# AM335x register map
Vendor: Texas Instruments; Series: Sitara AM335x; File version: 1.1
CPU: Cortex-A8 r0p0, little endian
Registers are 32-bit, read-write, reset 0x0 unless marked. A register's access mark holds for its fields unless they carry their own. Offsets are from the block's base; [hi:lo] are bit positions; 'fields as' and 'values as' point back to an identical list.

## EMIF0 — External Memory Interface 4D (EMIF) - DDR Controller
Base 0x4C000000
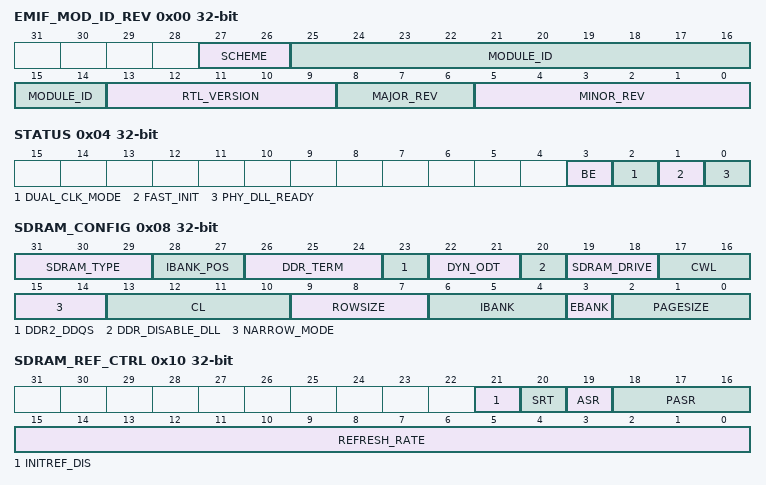
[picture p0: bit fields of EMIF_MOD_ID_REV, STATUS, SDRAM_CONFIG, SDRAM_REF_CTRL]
0x00 EMIF_MOD_ID_REV
  [27:26] SCHEME — bits 30..31 (R) Scheme indicator [0x1 = old scheme; 0x2 = current scheme]
  [25:14] MODULE_ID — bits 16..27 (R) EMIF module ID
  [13:9] RTL_VERSION — bits 11..15 (R) RTL Version
  [8:6] MAJOR_REV — bits 8..10 (R) Major Revision
  [5:0] MINOR_REV — bits 0..5 (R) Minor Revision
0x04 STATUS
  [3] BE — bit 31 (R) Big Endian mode [0x0 = little endian; 0x1 = big endian]
  [2] DUAL_CLK_MODE — bit 30 (R) Dual Clock mode [0x0 = synchronous; 0x1 = asynchronous]
  [1] FAST_INIT — bit 29 (R) Fast Init enabled [0x0 = disabled; 0x1 = enabled]
  [0] PHY_DLL_READY — bit 2 (R) DDR PHY Ready [0x0 = not ready; 0x1 = ready]
0x08 SDRAM_CONFIG
  [31:29] SDRAM_TYPE — bits 29..31 (RW) SDRAM Type selection [see e_SDRAM_TYPE]
  [28:27] IBANK_POS — bits 27..28 (RW) Internal bank position [see e_IBANK_POS]
  [26:24] DDR_TERM — bits 24..26 (RW) Termination resistor [see e_DDR_TERM]
  [23] DDR2_DDQS — bit 23 (RW) DDR2 diff DQS enable [0x0 = single ended; 0x1 = differential]
  [22:21] DYN_ODT — bits 21..22 (RW) DDR3 Dynamic ODT [see e_DYN_ODT]
  [20] DDR_DISABLE_DLL — bit 20 (RW) Disable DLL select [0x0 = enabled; 0x1 = disabled]
  [19:18] SDRAM_DRIVE — bits 18..19 (RW) Drive strength [see e_SDRAM_DRIVE]
  [17:16] CWL — bits 16..17 (RW) DDR3 CAS Write latency [see e_CWL]
  [15:14] NARROW_MODE — bits 14..15 (RW) Data bus width [0x0 = 32-bit; 0x1 = 16-bit]
  [13:10] CL — bits 10..13 (RW) CAS Latency [see e_CL]
  [9:7] ROWSIZE — bits 7..9 (RW) Row Size [see e_ROWSIZE]
  [6:4] IBANK — bits 4..6 (RW) Internal Bank setup [see e_IBANK]
  [3] EBANK — bit 3 (RW) External chip select [0x0 = CS0 only; 0x1 = CS0 and CS1]
  [2:0] PAGESIZE — bits 0..2 (RW) Page Size [see e_PAGESIZE]
0x0C SDRAM_CONFIG_2
  [0] EBANK_POS — bit 27 (RW) External bank position [0x0 = lower OCP address; 0x1 = higher OCP address]
0x10 SDRAM_REF_CTRL
  [21] INITREF_DIS — bit 31 (RW) Initialization and Refresh disable
  [20] SRT — bit 29 (RW) Self-refresh temperature range
  [19] ASR — bit 28 (RW) Auto Self Refresh enable
  [18:16] PASR — bits 24..26 (RW) Partial Array Self Refresh [see e_PASR]
  [15:0] REFRESH_RATE — bits 0..15 (RW) Refresh Rate
0x14 SDRAM_REF_CTRL_SHDW
  [15:0] REFRESH_RATE_SHADOW — bits 0..15 (RW) Shadow field for reg_refresh_rate
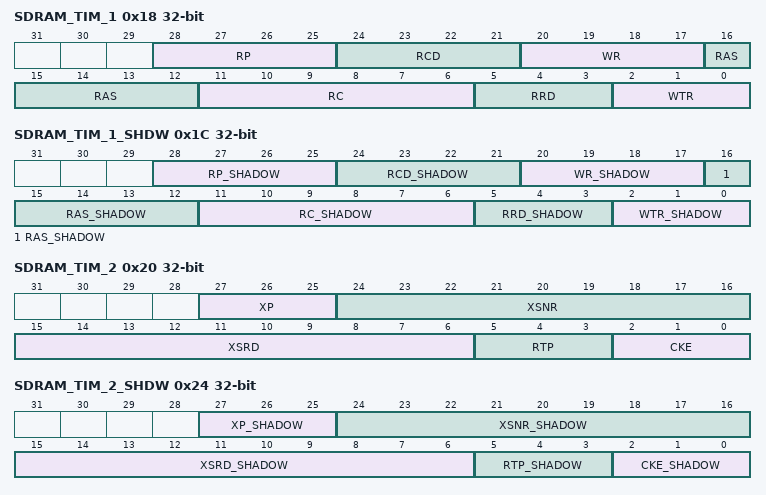
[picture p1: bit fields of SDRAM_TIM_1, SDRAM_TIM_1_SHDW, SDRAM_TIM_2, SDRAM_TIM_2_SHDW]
0x18 SDRAM_TIM_1
  [28:25] RP — bits 25..28 (RW) Precharge to Activate
  [24:21] RCD — bits 21..24 (RW) Activate to Read/Write
  [20:17] WR — bits 17..20 (RW) Write to Pre-charge
  [16:12] RAS — bits 12..16 (RW) Activate to Pre-charge
  [11:6] RC — bits 6..11 (RW) Activate to Activate
  [5:3] RRD — bits 3..5 (RW) Activate to Activate delay for different bank
  [2:0] WTR — bits 0..2 (RW) Write to Read delay
0x1C SDRAM_TIM_1_SHDW
  [28:25] RP_SHADOW — bits 25..28 (RW) Shadow field for RP
  [24:21] RCD_SHADOW — bits 21..24 (RW) Shadow field for RCD
  [20:17] WR_SHADOW — bits 17..20 (RW) Shadow field for WR
  [16:12] RAS_SHADOW — bits 12..16 (RW) Shadow field for RAS
  [11:6] RC_SHADOW — bits 6..11 (RW) Shadow field for RC
  [5:3] RRD_SHADOW — bits 3..5 (RW) Shadow field for RRD
  [2:0] WTR_SHADOW — bits 0..2 (RW) Shadow field for WTR
0x20 SDRAM_TIM_2
  [27:25] XP — bits 28..30 (RW) Powerdown exit delay
  [24:16] XSNR — bits 16..24 (RW) Self-Refresh exit delay
  [15:6] XSRD — bits 6..15 (RW) Self-Refresh exit to Read
  [5:3] RTP — bits 3..5 (RW) Read to Precharge
  [2:0] CKE — bits 0..2 (RW) CKE changes delay
0x24 SDRAM_TIM_2_SHDW
  [27:25] XP_SHADOW — bits 28..30 (RW) Shadow field for XP
  [24:16] XSNR_SHADOW — bits 16..24 (RW) Shadow field for XSNR
  [15:6] XSRD_SHADOW — bits 6..15 (RW) Shadow field for XSRD
  [5:3] RTP_SHADOW — bits 3..5 (RW) Shadow field for RTP
  [2:0] CKE_SHADOW — bits 0..2 (RW) Shadow field for CKE
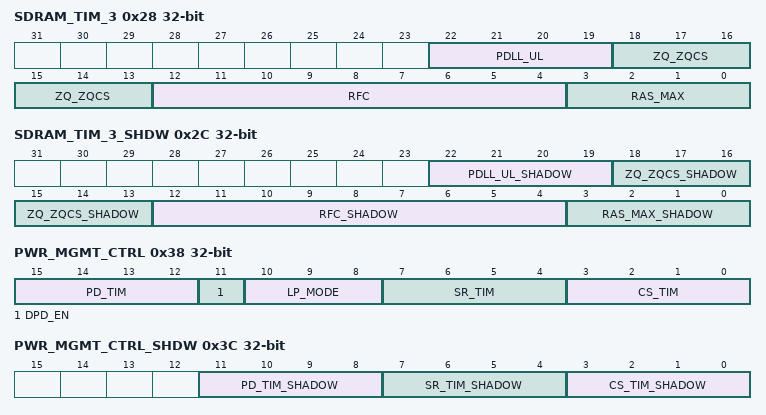
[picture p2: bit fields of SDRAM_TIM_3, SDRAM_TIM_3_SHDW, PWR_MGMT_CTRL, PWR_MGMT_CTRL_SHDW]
0x28 SDRAM_TIM_3
  [22:19] PDLL_UL — bits 28..31 (RW) PHY DLL unlock cycles
  [18:13] ZQ_ZQCS — bits 15..20 (RW) ZQCS command cycles
  [12:4] RFC — bits 4..12 (RW) Refresh/Activate delay
  [3:0] RAS_MAX — bits 0..3 (RW) Max Activate to Precharge
0x2C SDRAM_TIM_3_SHDW
  [22:19] PDLL_UL_SHADOW — bits 28..31 (RW) Shadow field for PDLL_UL
  [18:13] ZQ_ZQCS_SHADOW — bits 15..20 (RW) Shadow field for ZQ_ZQCS
  [12:4] RFC_SHADOW — bits 4..12 (RW) Shadow field for RFC
  [3:0] RAS_MAX_SHADOW — bits 0..3 (RW) Shadow field for RAS_MAX
0x38 PWR_MGMT_CTRL
  [15:12] PD_TIM — bits 12..15 (RW) Power-Down timer [see e_PWR_TIMER]
  [11] DPD_EN — bit 11 (RW) Deep Power Down enable
  [10:8] LP_MODE — bits 8..10 (RW) Power Management mode [see e_LP_MODE]
  [7:4] SR_TIM — bits 4..7 (RW) Self Refresh timer [see e_PWR_TIMER]
  [3:0] CS_TIM — bits 0..3 (RW) Clock Stop timer [see e_PWR_TIMER]
0x3C PWR_MGMT_CTRL_SHDW
  [11:8] PD_TIM_SHADOW — bits 8..11 (RW) Shadow field for PD_TIM
  [7:4] SR_TIM_SHADOW — bits 4..7 (RW) Shadow field for SR_TIM
  [3:0] CS_TIM_SHADOW — bits 0..3 (RW) Shadow field for CS_TIM
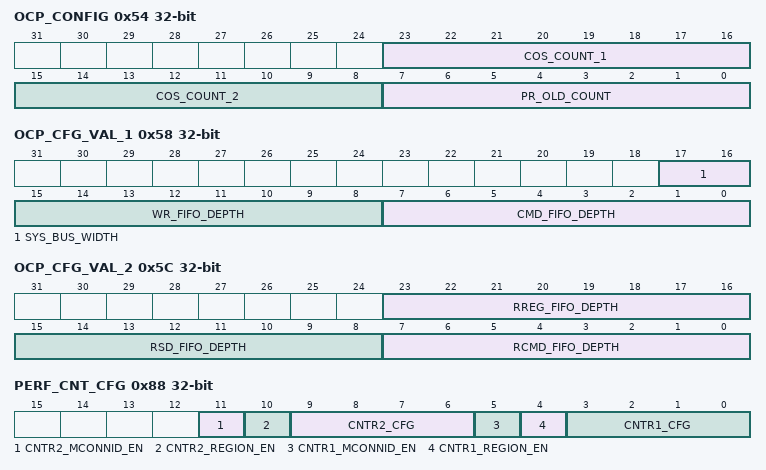
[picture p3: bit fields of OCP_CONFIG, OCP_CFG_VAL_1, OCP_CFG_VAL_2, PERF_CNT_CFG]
0x54 OCP_CONFIG
  [23:16] COS_COUNT_1 — bits 16..23 (RW) Priority Counter COS 1
  [15:8] COS_COUNT_2 — bits 8..15 (RW) Priority Counter COS 2
  [7:0] PR_OLD_COUNT — bits 0..7 (RW) Priority Raise Old Counter
0x58 OCP_CFG_VAL_1
  [17:16] SYS_BUS_WIDTH — bits 30..31 (R) L3 OCP data bus width [see e_SYS_BUS_WIDTH]
  [15:8] WR_FIFO_DEPTH — bits 8..15 (R) Write Data FIFO depth
  [7:0] CMD_FIFO_DEPTH — bits 0..7 (R) Command FIFO depth
0x5C OCP_CFG_VAL_2
  [23:16] RREG_FIFO_DEPTH — bits 16..23 (R) Register Read FIFO depth
  [15:8] RSD_FIFO_DEPTH — bits 8..15 (R) SDRAM Read Data FIFO depth
  [7:0] RCMD_FIFO_DEPTH — bits 0..7 (R) Read Command FIFO depth
0x80 PERF_CNT_1
  [31:0] COUNTER1 — bits 0..31 (R) Performance counter 1
0x84 PERF_CNT_2
  [31:0] COUNTER2 — bits 0..31 (R) Performance counter 2
0x88 PERF_CNT_CFG
  [11] CNTR2_MCONNID_EN — bit 31 (RW) Counter 2 MConnID enable
  [10] CNTR2_REGION_EN — bit 30 (RW) Counter 2 region enable
  [9:6] CNTR2_CFG — bits 16..19 (RW) Counter 2 config
  [5] CNTR1_MCONNID_EN — bit 15 (RW) Counter 1 MConnID enable
  [4] CNTR1_REGION_EN — bit 14 (RW) Counter 1 region enable
  [3:0] CNTR1_CFG — bits 0..3 (RW) Counter 1 config
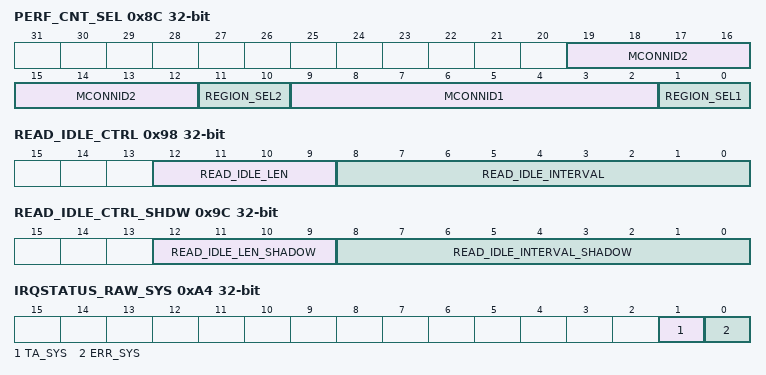
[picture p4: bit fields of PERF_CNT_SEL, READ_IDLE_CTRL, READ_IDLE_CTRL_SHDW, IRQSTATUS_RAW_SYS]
0x8C PERF_CNT_SEL
  [19:12] MCONNID2 — bits 24..31 (RW) MConnID for Counter 2
  [11:10] REGION_SEL2 — bits 16..17 (RW) MMddrSpace for Counter 2
  [9:2] MCONNID1 — bits 8..15 (RW) MConnID for Counter 1
  [1:0] REGION_SEL1 — bits 0..1 (RW) MMddrSpace for Counter 1
0x90 PERF_CNT_TIM
  [31:0] TOTAL_TIME — bits 0..31 (R) Total m_clk cycles counter
0x98 READ_IDLE_CTRL
  [12:9] READ_IDLE_LEN — bits 16..19 (RW) Read idle length
  [8:0] READ_IDLE_INTERVAL — bits 0..8 (RW) Read idle interval
0x9C READ_IDLE_CTRL_SHDW
  [12:9] READ_IDLE_LEN_SHADOW — bits 16..19 (RW) Shadow field for read idle length
  [8:0] READ_IDLE_INTERVAL_SHADOW — bits 0..8 (RW) Shadow field for read idle interval
0xA4 IRQSTATUS_RAW_SYS
  [1] TA_SYS — bit 1 (RW) Raw status of system OCP interrupt.
  [0] ERR_SYS — bit 0 (RW) Raw status of system OCP interrupt.
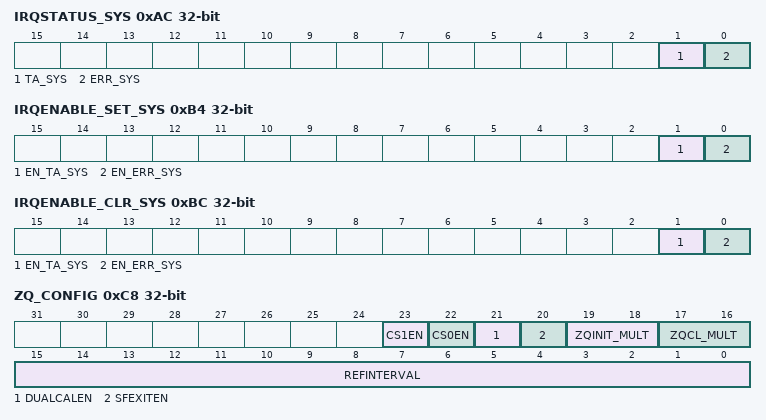
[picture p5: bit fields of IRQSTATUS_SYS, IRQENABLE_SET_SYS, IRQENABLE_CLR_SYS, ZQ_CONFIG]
0xAC IRQSTATUS_SYS
  [1] TA_SYS — bit 1 (RW) Enabled status of system OCP interrupt.
  [0] ERR_SYS — bit 0 (RW) Enabled status of system OCP interrupt.
0xB4 IRQENABLE_SET_SYS
  [1] EN_TA_SYS — bit 1 (RW) Enable set for system OCP interrupt.
  [0] EN_ERR_SYS — bit 0 (RW) Enable set for system OCP interrupt.
0xBC IRQENABLE_CLR_SYS
  [1] EN_TA_SYS — bit 1 (RW) Enable clear for system OCP interrupt.
  [0] EN_ERR_SYS — bit 0 (RW) Enable clear for system OCP interrupt.r
0xC8 ZQ_CONFIG
  [23] CS1EN — bit 31 (RW) ZQ cal for CS1 enable
  [22] CS0EN — bit 30 (RW) ZQ cal for CS0 enable
  [21] DUALCALEN — bit 29 (RW) Dual Calibration enable
  [20] SFEXITEN — bit 28 (RW) ZQCL on power-down exit
  [19:18] ZQINIT_MULT — bits 18..19 (RW) Indicates the number of ZQCL intervals that make up a ZQINIT
  [17:16] ZQCL_MULT — bits 16..17 (RW) Determines number of ZQCS intervals that make up ZQCL/ZQINIT intervals
  [15:0] REFINTERVAL — bits 0..15 (RW) Refresh periods between ZQCS
0xD4 RDWRLVL_RAMP_WIN
  [12:0] RDWRLVLINC_RMP_WIN — bits 0..12 (R) Incremental leveling ramp window
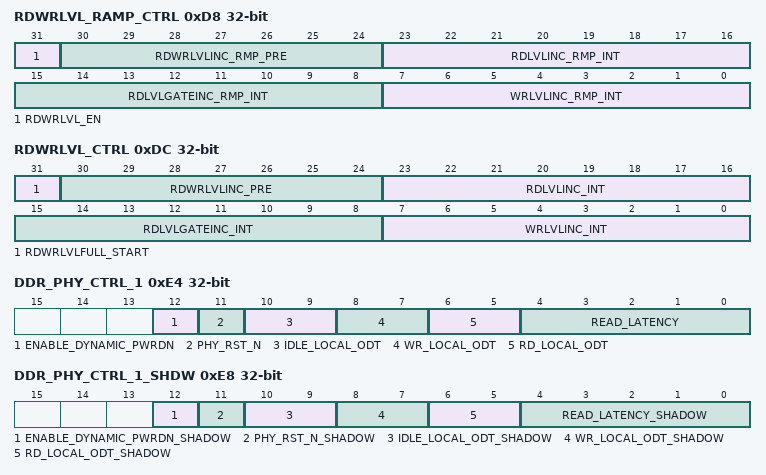
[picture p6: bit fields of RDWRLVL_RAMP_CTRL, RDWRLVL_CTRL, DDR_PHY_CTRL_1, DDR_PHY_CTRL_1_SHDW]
0xD8 RDWRLVL_RAMP_CTRL
  [31] RDWRLVL_EN — bit 31 (RW) Read-Write Leveling enable
  [30:24] RDWRLVLINC_RMP_PRE — bits 24..30 (RW) Incremental leveling pre-scalar
  [23:16] RDLVLINC_RMP_INT — bits 16..23 (RW) Incremental read data eye training interval
  [15:8] RDLVLGATEINC_RMP_INT — bits 8..15 (RW) Incremental read DQS gate training interval
  [7:0] WRLVLINC_RMP_INT — bits 0..7 (RW) Incremental write leveling interval
0xDC RDWRLVL_CTRL
  [31] RDWRLVLFULL_START — bit 31 (RW) Full leveling trigger
  [30:24] RDWRLVLINC_PRE — bits 24..30 (RW) Incremental leveling pre-scalar
  [23:16] RDLVLINC_INT — bits 16..23 (RW) Incremental read data eye training interval
  [15:8] RDLVLGATEINC_INT — bits 8..15 (RW) Incremental read DQS gate training interval
  [7:0] WRLVLINC_INT — bits 0..7 (RW) Incremental write leveling interval
0xE4 DDR_PHY_CTRL_1
  [12] ENABLE_DYNAMIC_PWRDN — bit 20 (RW) Dynamic IO power down
  [11] PHY_RST_N — bit 15 (RW) PHY reset control
  [10:9] IDLE_LOCAL_ODT — bits 12..13 (RW) Value to drive on the
  [8:7] WR_LOCAL_ODT — bits 10..11 (RW) This bit controls the value assigned to the reg_phy_wr_local_odt
  [6:5] RD_LOCAL_ODT — bits 8..9 (RW) Read local ODT value [see e_LOCAL_ODT]
  [4:0] READ_LATENCY — bits 0..4 (RW) This field defines the latency for read data from DDR SDRAM in
0xE8 DDR_PHY_CTRL_1_SHDW
  [12] ENABLE_DYNAMIC_PWRDN_SHADOW — bit 20 (RW) Dynamically enables powering down the IO receiver when not
  [11] PHY_RST_N_SHADOW — bit 15 (RW) Writing a 1 to this bit will hold the PHY macros in reset.
  [10:9] IDLE_LOCAL_ODT_SHADOW — bits 12..13 (RW) Value to drive on the
  [8:7] WR_LOCAL_ODT_SHADOW — bits 10..11 (RW) This bit controls the value assigned to the reg_phy_wr_local_odt
  [6:5] RD_LOCAL_ODT_SHADOW — bits 8..9 (RW) Value to drive on the
  [4:0] READ_LATENCY_SHADOW — bits 0..4 (RW) This field defines the latency for read data from DDR SDRAM in
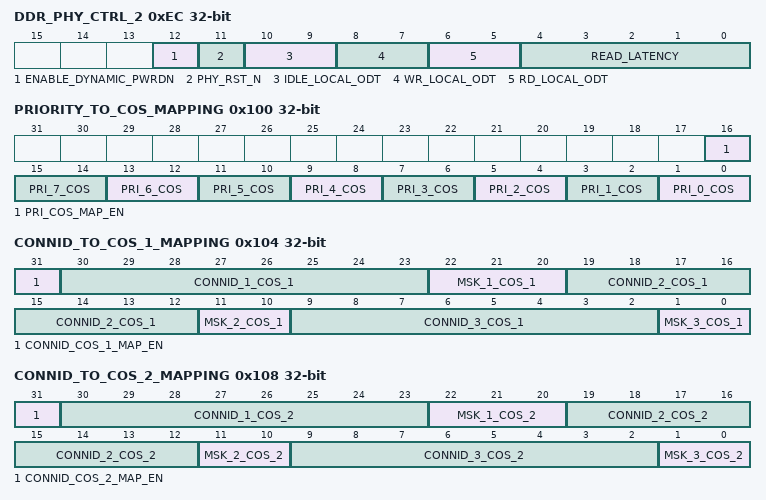
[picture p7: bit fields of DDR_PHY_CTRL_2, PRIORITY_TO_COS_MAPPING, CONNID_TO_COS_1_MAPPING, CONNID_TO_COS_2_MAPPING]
0xEC DDR_PHY_CTRL_2
  fields as DDR_PHY_CTRL_1
0x100 PRIORITY_TO_COS_MAPPING
  [16] PRI_COS_MAP_EN — bit 31 (RW) Priority mapping enable
  [15:14] PRI_7_COS — bits 14..15 (RW) Priority 7 COS mapping [see e_COS_MAPPING]
  [13:12] PRI_6_COS — bits 12..13 (RW) Priority 6 COS mapping [see e_COS_MAPPING]
  [11:10] PRI_5_COS — bits 10..11 (RW) Priority 5 COS mapping [see e_COS_MAPPING]
  [9:8] PRI_4_COS — bits 8..9 (RW) Priority 4 COS mapping [see e_COS_MAPPING]
  [7:6] PRI_3_COS — bits 6..7 (RW) Priority 3 COS mapping [see e_COS_MAPPING]
  [5:4] PRI_2_COS — bits 4..5 (RW) Priority 2 COS mapping [see e_COS_MAPPING]
  [3:2] PRI_1_COS — bits 2..3 (RW) Priority 1 COS mapping [see e_COS_MAPPING]
  [1:0] PRI_0_COS — bits 0..1 (RW) Priority 0 COS mapping [see e_COS_MAPPING]
0x104 CONNID_TO_COS_1_MAPPING
  [31] CONNID_COS_1_MAP_EN — bit 31 (RW) ConnID mapping enable
  [30:23] CONNID_1_COS_1 — bits 23..30 (RW) ConnID value 1 COS 1
  [22:20] MSK_1_COS_1 — bits 20..22 (RW) Mask for ConnID 1 COS 1 [see e_CONNID_MASK_EXT]
  [19:12] CONNID_2_COS_1 — bits 12..19 (RW) ConnID value 2 COS 1
  [11:10] MSK_2_COS_1 — bits 10..11 (RW) Mask for ConnID 2 COS 1 [see e_CONNID_MASK]
  [9:2] CONNID_3_COS_1 — bits 2..9 (RW) ConnID value 3 COS 1
  [1:0] MSK_3_COS_1 — bits 0..1 (RW) Mask for ConnID 3 COS 1 [see e_CONNID_MASK]
0x108 CONNID_TO_COS_2_MAPPING
  [31] CONNID_COS_2_MAP_EN — bit 31 (RW) ConnID mapping enable
  [30:23] CONNID_1_COS_2 — bits 23..30 (RW) ConnID value 1 COS 2
  [22:20] MSK_1_COS_2 — bits 20..22 (RW) Mask for ConnID 1 COS 2 [see e_CONNID_MASK_EXT]
  [19:12] CONNID_2_COS_2 — bits 12..19 (RW) ConnID value 2 COS 2
  [11:10] MSK_2_COS_2 — bits 10..11 (RW) Mask for ConnID 2 COS 2 [see e_CONNID_MASK]
  [9:2] CONNID_3_COS_2 — bits 2..9 (RW) ConnID value 3 COS 2
  [1:0] MSK_3_COS_2 — bits 0..1 (RW) Mask for ConnID 3 COS 2 [see e_CONNID_MASK]
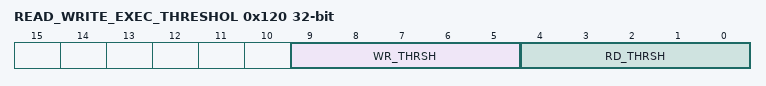
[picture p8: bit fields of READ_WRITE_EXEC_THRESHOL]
0x120 READ_WRITE_EXEC_THRESHOL — READ_WRITE_EXEC_THRESHOLD Register
  [9:5] WR_THRSH — bits 8..12 (RW) Write threshold
  [4:0] RD_THRSH — bits 0..4 (RW) Read threshold
